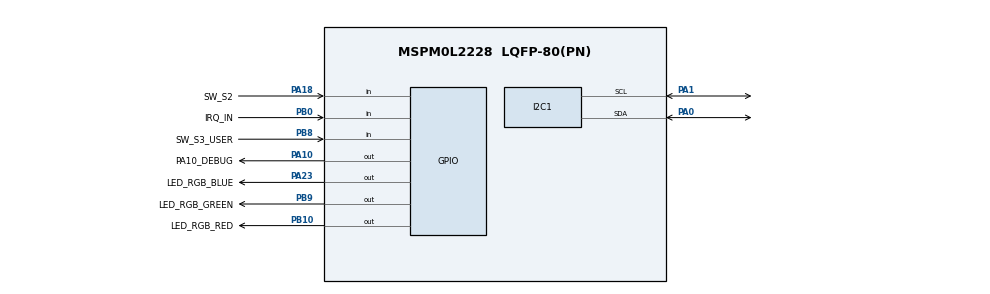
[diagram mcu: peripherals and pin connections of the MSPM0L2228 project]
//@cliArgs --device "MSPM0L222X" --package "LQFP-80(PN)" --part "Default"
//@v2CliArgs --device "MSPM0L2228" --package "LQFP-80(PN)"
// @cliArgs --board /ti/boards/LP_MSPM0L2228 --rtos nortos

/**
 * Import the modules used in this configuration.
 */
const Board         = scripting.addModule("/ti/driverlib/Board");
const CRCP          = scripting.addModule("/ti/driverlib/CRCP");
const GPIO          = scripting.addModule("/ti/driverlib/GPIO", {}, false);
const GPIO1         = GPIO.addInstance();
const GPIO2         = GPIO.addInstance();
const I2C           = scripting.addModule("/ti/driverlib/I2C", {}, false);
const I2C1          = I2C.addInstance();
const SYSCTL        = scripting.addModule("/ti/driverlib/SYSCTL");
const TIMER         = scripting.addModule("/ti/driverlib/TIMER", {}, false);
const TIMER1        = TIMER.addInstance();
const TIMER2        = TIMER.addInstance();
const ProjectConfig = scripting.addModule("/ti/project_config/ProjectConfig");

/**
 * Write custom configuration values to the imported modules.
 */
Board.configureUnused    = true;
Board.genPeriphPinFile   = true;
Board.peripheral.$assign = "DEBUGSS";
Board.genFileMod.$name   = "ti_driverlib_BoardPins0";

CRCP.seed = 0xFFFFFFFF;

GPIO1.$name                              = "GPIO_B";
GPIO1.associatedPins.create(4);
GPIO1.associatedPins[0].$name            = "LED_RGB_GREEN";
GPIO1.associatedPins[0].assignedPin      = "9";
GPIO1.associatedPins[0].assignedPort     = "PORTB";
GPIO1.associatedPins[0].pin.$assign      = "PB9";
GPIO1.associatedPins[1].$name            = "LED_RGB_RED";
GPIO1.associatedPins[1].assignedPin      = "10";
GPIO1.associatedPins[1].assignedPort     = "PORTB";
GPIO1.associatedPins[1].pin.$assign      = "PB10";
GPIO1.associatedPins[2].direction        = "INPUT";
GPIO1.associatedPins[2].interruptEn      = true;
GPIO1.associatedPins[2].polarity         = "RISE_FALL";
GPIO1.associatedPins[2].internalResistor = "PULL_UP";
GPIO1.associatedPins[2].inputFilter      = "3_CYCLES";
GPIO1.associatedPins[2].$name            = "SW_S3_USER";
GPIO1.associatedPins[2].assignedPin      = "8";
GPIO1.associatedPins[2].assignedPort     = "PORTB";
GPIO1.associatedPins[2].pin.$assign      = "PB8";
GPIO1.associatedPins[3].assignedPin      = "0";
GPIO1.associatedPins[3].$name            = "IRQ_IN";
GPIO1.associatedPins[3].direction        = "INPUT";
GPIO1.associatedPins[3].internalResistor = "PULL_UP";
GPIO1.associatedPins[3].interruptEn      = true;
GPIO1.associatedPins[3].polarity         = "FALL";
GPIO1.associatedPins[3].inputFilter      = "3_CYCLES";
GPIO1.associatedPins[3].assignedPort     = "PORTB";
GPIO1.associatedPins[3].pin.$assign      = "PB0";

GPIO2.$name                          = "GPIO_A";
GPIO2.associatedPins.create(3);
GPIO2.associatedPins[0].$name        = "SW_S2";
GPIO2.associatedPins[0].direction    = "INPUT";
GPIO2.associatedPins[0].assignedPort = "PORTA";
GPIO2.associatedPins[0].assignedPin  = "18";
GPIO2.associatedPins[0].inputFilter  = "3_CYCLES";
GPIO2.associatedPins[0].interruptEn  = true;
GPIO2.associatedPins[0].polarity     = "RISE_FALL";
GPIO2.associatedPins[0].pin.$assign  = "PA18";
GPIO2.associatedPins[1].initialValue = "SET";
GPIO2.associatedPins[1].assignedPort = "PORTA";
GPIO2.associatedPins[1].assignedPin  = "10";
GPIO2.associatedPins[1].$name        = "PA10_DEBUG";
GPIO2.associatedPins[1].pin.$assign  = "PA10";
GPIO2.associatedPins[2].$name        = "LED_RGB_BLUE";
GPIO2.associatedPins[2].assignedPort = "PORTA";
GPIO2.associatedPins[2].assignedPin  = "23";
GPIO2.associatedPins[2].pin.$assign  = "PA23";

I2C1.basicEnableController             = true;
I2C1.basicTargetAddress                = 0x0;
I2C1.advTargetClkStretch               = false;
I2C1.$name                             = "I2C_CONTROLLER";
I2C1.timeoutACount                     = 255;
I2C1.timeoutBCount                     = 255;
I2C1.advControllerClkStretch           = false;
I2C1.intController                     = ["NACK","RXFIFO_TRIGGER","RX_DONE","TX_DONE"];
I2C1.advControllerTXFIFOTRIG           = "BYTES_1";
I2C1.peripheral.$assign                = "I2C0";
I2C1.peripheral.sdaPin.$assign         = "PA0";
I2C1.peripheral.sclPin.$assign         = "PA1";

SYSCTL.peripheral.$assign = "SYSCTL";
scripting.suppress("Note: VBAT needs to be powered for LFCLK operation\\.", SYSCTL, "LFCLKSource");

TIMER1.interrupts                  = ["ZERO"];
TIMER1.timerPeriod                 = "10 ms";
TIMER1.timerClkSrc                 = "LFCLK";
TIMER1.event1ControllerInterruptEn = ["ZERO_EVENT"];
TIMER1.$name                       = "TIMG_DELAY_BLOCKING";
TIMER1.peripheral.$assign          = "TIMG0";

TIMER2.interrupts                  = ["ZERO"];
TIMER2.timerPeriod                 = "10 ms";
TIMER2.timerClkSrc                 = "LFCLK";
TIMER2.event1ControllerInterruptEn = ["ZERO_EVENT"];
TIMER2.$name                       = "TIMG_DELAY_NO_BLOCKING";
TIMER2.peripheral.$assign          = "TIMG4";

ProjectConfig.switchCondition = true;
scripting.suppress("Migrating requires going through the Switch Board or Device menu in the Device View section\\.", ProjectConfig, "deviceSpin");
